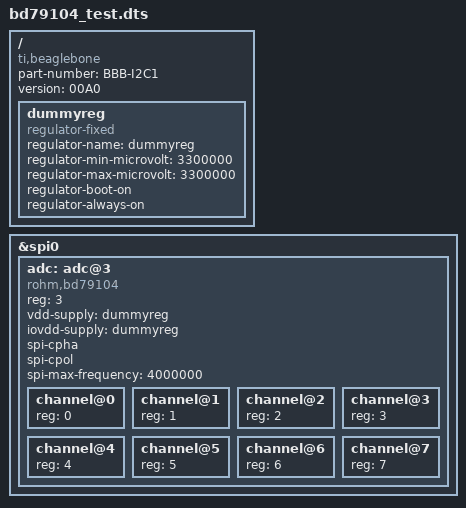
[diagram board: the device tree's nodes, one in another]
/dts-v1/;
/plugin/;

#include <dt-bindings/pinctrl/omap.h>
#include <dt-bindings/pinctrl/am33xx.h>
#include <dt-bindings/interrupt-controller/irq.h>
#include <dt-bindings/gpio/gpio.h>

/{ /* this is our device tree overlay root node */

	compatible = "ti,beaglebone", "ti,beaglebone-black";
	part-number = "BBB-I2C1"; // you can choose any name here but it should be memorable
	version = "00A0";

	fragment@0 {
		target = <&spi0>;

		__overlay__ {
			adc: adc@3 {
				compatible = "rohm,bd79104";
				reg = <3>;
				/* GPIO 1_29 - (connector 8, pin 26) for irq */
/*				interrupt-parent = <&gpio1>;
				interrupts = <29 8>; */
				vdd-supply = <&dummyreg>;
				iovdd-supply = <&dummyreg>;
				spi-cpha;
				spi-cpol;
				spi-max-frequency = <4000000>;

				channel@0 {
					reg = <0>;
				};
				channel@1 {
					reg = <1>;
				};
				channel@2 {
					reg = <2>;
				};
				channel@3 {
					reg = <3>;
				};
				channel@4 {
					reg = <4>;
				};
				channel@5 {
					reg = <5>;
				};
				channel@6 {
					reg = <6>;
				};
				channel@7 {
					reg = <7>;
				};
			};
		};
	};
	fragment@3 {
		target-path = "/";
		__overlay__ {
			dummyreg: dummyreg {
				compatible = "regulator-fixed";
				regulator-name = "dummyreg";
				regulator-min-microvolt = <3300000>;
				regulator-max-microvolt = <3300000>;
				regulator-boot-on;
				regulator-always-on;
			};
		};
	};
}; /* root node end */
